# MWPR1516 register map
Vendor: Freescale Semiconductor, Inc.; Series: Kinetis; File version: 1.6
CPU: CM0PLUS r0p0, little endian, no MPU, no FPU, VTOR, 2 interrupt priority bits
Registers are 8-bit, read-write, reset 0x0 unless marked. A register's access mark holds for its fields unless they carry their own. Offsets are from the block's base; [hi:lo] are bit positions.

## GPIOA — General Purpose Input/Output
Base 0x4000F000; register names take the prefix GPIOA_
0x00 PDOR 32-bit — Port Data Output Register
  [31:0] PDO — Port Data Output
    0=Logic level 0 is driven on pin, provided pin is configured for general-purpose output; 1=Logic level 1 is driven on pin, provided pin is configured for general-purpose output
0x04 PSOR 32-bit wo — Port Set Output Register
  [31:0] PTSO — Port Set Output
    0=Corresponding bit in PDORn does not change; 1=Corresponding bit in PDORn is set to logic 1
0x08 PCOR 32-bit wo — Port Clear Output Register
  [31:0] PTCO — Port Clear Output
    0=Corresponding bit in PDORn does not change; 1=Corresponding bit in PDORn is cleared to logic 0
0x0C PTOR 32-bit wo — Port Toggle Output Register
  [31:0] PTTO — Port Toggle Output
    0=Corresponding bit in PDORn does not change; 1=Corresponding bit in PDORn is set to the inverse of its existing logic state
0x10 PDIR 32-bit ro — Port Data Input Register
  [31:0] PDI — Port Data Input
    0=Pin logic level is logic 0, or is not configured for use by digital function; 1=Pin logic level is logic 1
0x14 PDDR 32-bit — Port Data Direction Register
  [31:0] PDD — Port Data Direction
    0=Pin is configured as general-purpose input, for the GPIO function; 1=Pin is configured as general-purpose output, for the GPIO function
0x18 PIDR 32-bit reset 0x1FFF — Port Input Disable Register
  [31:0] PID — Port Input Disable
    0=Pin is configured for General Purpose Input, provided the pin is configured for any digital function; 1=Pin is not configured as General Purpose Input.Corresponding Port Data Input Register bit will read zero

## FTMRE — Flash Memory
Base 0x40020000; register names take the prefix FTMRE_
0x01 FCCOBIX — Flash CCOB Index Register
  [2:0] CCOBIX — Common Command Register Index
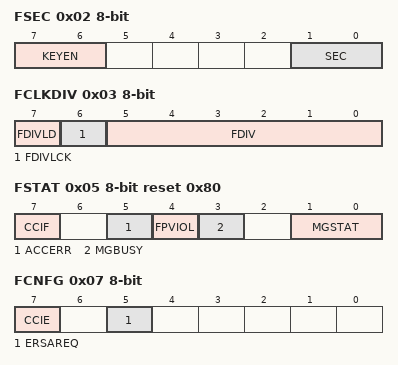
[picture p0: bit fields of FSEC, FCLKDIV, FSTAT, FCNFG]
0x02 FSEC ro reset not defined — Flash Security Register
  [7:6] KEYEN — Backdoor Key Security Enable Bits
    0=Disabled; 1=Disabled; 2=Enabled; 3=Disabled
  [1:0] SEC — Flash Security Bits
    0=Secured; 1=Secured; 2=Unsecured; 3=Secured
0x03 FCLKDIV — Flash Clock Divider Register
  [7] FDIVLD ro — Clock Divider Loaded
    0=FCLKDIV register has not been written since the last reset; 1=FCLKDIV register has been written since the last reset
  [6] FDIVLCK — Clock Divider Locked
    0=FDIV field is open for writing; 1=FDIV value is locked and cannot be changed. After the lock bit is set high, only reset can clear this bit and restore writability to the FDIV field in user mode.
  [5:0] FDIV — Clock Divider Bits
0x05 FSTAT reset 0x80 — Flash Status Register
  [7] CCIF — Command Complete Interrupt Flag
    0=Flash command is in progress; 1=Flash command has completed
  [5] ACCERR — Flash Access Error Flag
    0=No access error is detected; 1=Access error is detected
  [4] FPVIOL — Flash Protection Violation Flag
    0=No protection violation is detected; 1=Protection violation is detected
  [3] MGBUSY ro — Memory Controller Busy Flag
    0=Memory controller is idle; 1=Memory controller is busy executing a flash command (CCIF = 0)
  [1:0] MGSTAT ro — Memory Controller Command Completion Status Flag
0x07 FCNFG — Flash Configuration Register
  [7] CCIE — Command Complete Interrupt Enable
    0=Command complete interrupt is disabled; 1=An interrupt will be requested whenever the CCIF flag in the FSTAT register is set
  [5] ERSAREQ ro — Debugger Mass Erase Request
    0=No request or request complete; 1=Request to run the Erase All Blocks command verify the erased state program the security byte in the Flash Configuration Field to the unsecure state release MCU security by setting FSEC[SEC] to the unsecure state
0x08 FCCOBLO — Flash Common Command Object Register: Low
  [7:0] CCOB — Common Command Object Bit 7:0
0x09 FCCOBHI — Flash Common Command Object Register:High
  [7:0] CCOB — Common Command Object Bit 15:8
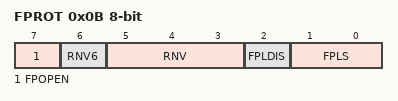
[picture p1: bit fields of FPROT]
0x0B FPROT (reset mask 0x38) — Flash Protection Register
  [7] FPOPEN — Flash Protection Operation Enable
    0=When FPOPEN is clear, the FPLDIS field defines unprotected address ranges as specified by the corresponding FPLS field; 1=When FPOPEN is set, the FPLDIS field enables protection for the address range specified by the corresponding FPLS field
  [6] RNV6 ro — Reserved Nonvolatile Bit
  [5:3] RNV ro — Reserved Nonvolatile Bit
  [2] FPLDIS — Flash Protection Lower Address Range Disable
    0=Protection/Unprotection enabled; 1=Protection/Unprotection disabled
  [1:0] FPLS — Flash Protection Lower Address Size
0x0F FOPT ro reset not defined — Flash Option Register
  [7:0] NV — Nonvolatile Bits
